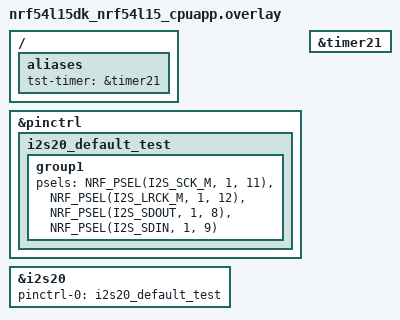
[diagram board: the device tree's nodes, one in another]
/*
 * Copyright (c) 2025 Nordic Semiconductor ASA
 *
 * SPDX-License-Identifier: LicenseRef-Nordic-5-Clause
 */

/ {
	aliases {
		tst-timer = &timer21;
	};
};

&pinctrl {
	i2s20_default_test: i2s20_default_test {
		group1 {
			psels = <NRF_PSEL(I2S_SCK_M, 1, 11)>,
				<NRF_PSEL(I2S_LRCK_M, 1, 12)>,
				<NRF_PSEL(I2S_SDOUT, 1, 8)>,
				<NRF_PSEL(I2S_SDIN, 1, 9)>;
		};
	};
};

i2s_dut: &i2s20 {
	status = "okay";
	pinctrl-0 = <&i2s20_default_test>;
	pinctrl-names = "default";
};

&timer21 {
	status = "okay";
};
